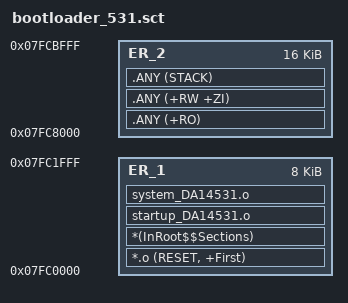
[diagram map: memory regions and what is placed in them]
LR_1 0x07FC0000 0x00008000 {    ; load region size_region
    ER_1 +0 0x00002000 {        ; load address = execution address
        *.o (RESET, +First)
        *(InRoot$$Sections)
        startup_DA14531.o
        system_DA14531.o
    }

    ER_2 0x07FC8000 0x4000 {    ; push it to the end of SysRAM
        .ANY (+RO)
        .ANY (+RW +ZI)
        .ANY (STACK)
    }
}
